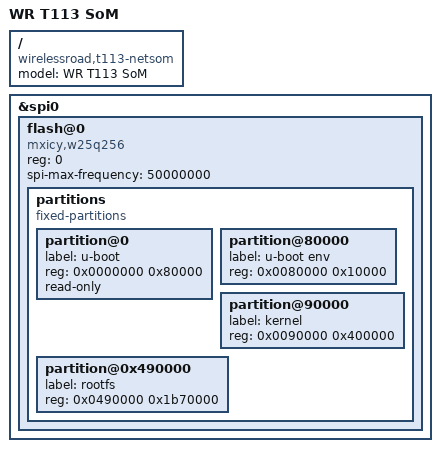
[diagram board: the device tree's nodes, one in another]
// SPDX-License-Identifier: (GPL-2.0+ OR MIT)
// Copyright (C) 2024 WirelessRoad.

/dts-v1/;

#include "sun8i-t113s-wr-netsom.dtsi"

/ {
	model = "WR T113 SoM";
	compatible = "wirelessroad,t113-netsom", "allwinner,sun8i-t113s";
};

&spi0 {
    flash@0 {
        #address-cells = <1>;
        #size-cells = <1>;
        compatible = "mxicy,w25q256", "jedec,spi-nor";
        reg = <0>;
        spi-max-frequency = <50000000>;
        partitions {
            compatible = "fixed-partitions";
            #address-cells = <1>;
            #size-cells = <1>;
            partition@0 {
                label = "u-boot";
                reg = <0x0000000 0x80000>;
                read-only;
            };
            partition@80000 {
                label = "u-boot env";
                reg = <0x0080000 0x10000>;
            };
            partition@90000 {
                label = "kernel";
                reg = <0x0090000 0x400000>;
            };
            partition@0x490000 {
                label = "rootfs";
                reg = <0x0490000 0x1b70000>;
            };
        };
    };
};
